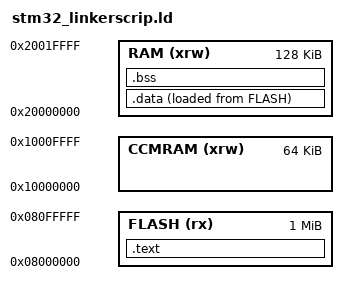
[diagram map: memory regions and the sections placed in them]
/* Entry Point */
ENTRY(Reset_Handler)

/* Highest address of the user mode stack */
_estack = ORIGIN(RAM) + LENGTH(RAM); /* end of "RAM" Ram type memory */

_Min_Heap_Size = 0x200; /* required amount of heap */
_Min_Stack_Size = 0x400; /* required amount of stack */

/* Memories definition */
MEMORY
{
  CCMRAM    (xrw)    : ORIGIN = 0x10000000,   LENGTH = 64K
  RAM    (xrw)    : ORIGIN = 0x20000000,   LENGTH = 128K
  FLASH    (rx)    : ORIGIN = 0x8000000,   LENGTH = 1024K
}

/* Sections */
SECTIONS
{
    .text :
    {
    	. = ALIGN(4);
        _stext = .;  
        *(.isr_vector)
        *(.text)
        *(.rodata)
        . = ALIGN(4);
        _etext = .;    
    }> FLASH

    .data :
    {
        _sdata = .;
        *(.data)
        . = ALIGN(4);
        _edata = .;
    }> RAM AT >FLASH
    .bss :
    {
        _sbss = .;
        *(.bss)
        . = ALIGN(4);
        _ebss = .;
    }> RAM
     /* Used by the startup to initialize data */
  _sidata = LOADADDR(.data);
}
